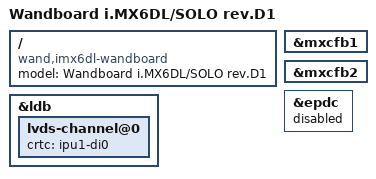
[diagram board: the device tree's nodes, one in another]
/*
 * Copyright 2013-2017 Freescale Semiconductor, Inc.
 * Copyright 2017 Wandboard, Org.
 *
 * Author: Fabio Estevam <fabio.estevam@freescale.com>
 *         Richard Hu <richard.hu@technexion.com>
 *
 * This program is free software; you can redistribute it and/or modify
 * it under the terms of the GNU General Public License version 2 as
 * published by the Free Software Foundation.
 *
 */

/dts-v1/;

#include <dt-bindings/interrupt-controller/irq.h>
#include "imx6dl.dtsi"
#include "imx6qdl-wandboard-revd1.dtsi"

/ {
	model = "Wandboard i.MX6DL/SOLO rev.D1";
	compatible = "wand,imx6dl-wandboard", "fsl,imx6dl";
};

&ldb {
	lvds-channel@0 {
		crtc = "ipu1-di0";
	};
};

&mxcfb1 {
	status = "okay";
};

&mxcfb2 {
	status = "okay";
};

#if 0
&mxcfb3 {
	status = "okay";
};

&mxcfb4 {
	status = "okay";
};
#endif

&epdc {
	status = "disabled";
};
